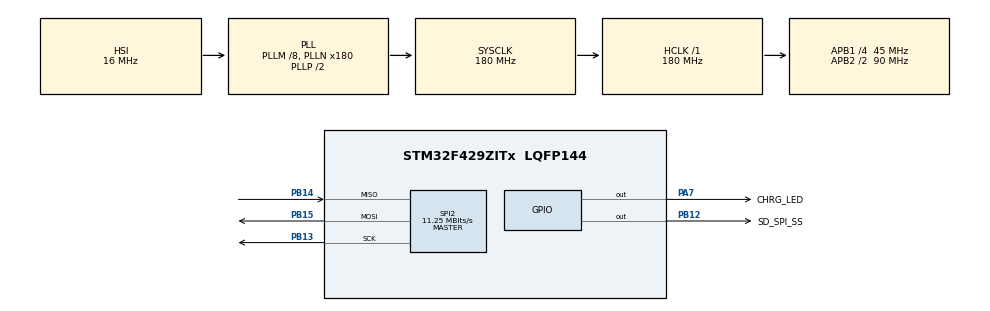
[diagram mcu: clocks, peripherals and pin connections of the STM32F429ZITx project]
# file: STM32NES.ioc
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FATFS._MAX_SS=512
FATFS._USE_LFN=1
FATFS._USE_STRFUNC=1
Mcu.Family=STM32F4
Mcu.Name=STM32F429ZITx
Mcu.Package=LQFP144
NVIC.PriorityGroup=NVIC_PRIORITYGROUP_4
PA7.GPIO_Label=CHRG_LED
PA7.PinState=GPIO_PIN_SET
PA7.Signal=GPIO_Output
PB12.GPIO_Label=SD_SPI_SS
PB12.PinState=GPIO_PIN_SET
PB12.Signal=GPIO_Output
PB13.Mode=Full_Duplex_Master
PB13.Signal=SPI2_SCK
PB14.Mode=Full_Duplex_Master
PB14.Signal=SPI2_MISO
PB15.Mode=Full_Duplex_Master
PB15.Signal=SPI2_MOSI
ProjectManager.HeapSize=0x200
ProjectManager.StackSize=0x400
ProjectManager.TargetToolchain=TrueSTUDIO
RCC.48MHZClocksFreq_Value=90000000
RCC.AHBFreq_Value=180000000
RCC.APB1CLKDivider=RCC_HCLK_DIV4
RCC.APB1Freq_Value=45000000
RCC.APB1TimFreq_Value=90000000
RCC.APB2CLKDivider=RCC_HCLK_DIV2
RCC.APB2Freq_Value=90000000
RCC.APB2TimFreq_Value=180000000
RCC.CortexFreq_Value=180000000
RCC.HCLKFreq_Value=180000000
RCC.HSE_VALUE=25000000
RCC.HSI_VALUE=16000000
RCC.LSE_VALUE=32768
RCC.PLLM=8
RCC.PLLN=180
RCC.SYSCLKFreq_VALUE=180000000
RCC.SYSCLKSource=RCC_SYSCLKSOURCE_PLLCLK
RCC.VCOOutputFreq_Value=360000000
SPI2.BaudRatePrescaler=SPI_BAUDRATEPRESCALER_4
SPI2.CalculateBaudRate=11.25 MBits/s
SPI2.Direction=SPI_DIRECTION_2LINES
SPI2.Mode=SPI_MODE_MASTER
SPI2.VirtualType=VM_MASTER
VP_FATFS_VS_Generic.Mode=User_defined
board=custom

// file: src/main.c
/* USER CODE BEGIN Header */
/**
 ******************************************************************************
 * @file           : main.c
 * @brief          : Main program body
 ******************************************************************************
 * This notice applies to any and all portions of this file
 * that are not between comment pairs USER CODE BEGIN and
 * USER CODE END. Other portions of this file, whether
 * inserted by the user or by software development tools
 * are owned by their respective copyright owners.
 *
 * Copyright (c) 2019 STMicroelectronics International N.V.
 * All rights reserved.
 *
 * Redistribution and use in source and binary forms, with or without
 * modification, are permitted, provided that the following conditions are met:
 *
 * 1. Redistribution of source code must retain the above copyright notice,
 *    this list of conditions and the following disclaimer.
 * 2. Redistributions in binary form must reproduce the above copyright notice,
 *    this list of conditions and the following disclaimer in the documentation
 *    and/or other materials provided with the distribution.
 * 3. Neither the name of STMicroelectronics nor the names of other
 *    contributors to this software may be used to endorse or promote products
 *    derived from this software without specific written permission.
 * 4. This software, including modifications and/or derivative works of this
 *    software, must execute solely and exclusively on microcontroller or
 *    microprocessor devices manufactured by or for STMicroelectronics.
 * 5. Redistribution and use of this software other than as permitted under
 *    this license is void and will automatically terminate your rights under
 *    this license.
 *
 * THIS SOFTWARE IS PROVIDED BY STMICROELECTRONICS AND CONTRIBUTORS "AS IS"
 * AND ANY EXPRESS, IMPLIED OR STATUTORY WARRANTIES, INCLUDING, BUT NOT
 * LIMITED TO, THE IMPLIED WARRANTIES OF MERCHANTABILITY, FITNESS FOR A
 * PARTICULAR PURPOSE AND NON-INFRINGEMENT OF THIRD PARTY INTELLECTUAL PROPERTY
 * RIGHTS ARE DISCLAIMED TO THE FULLEST EXTENT PERMITTED BY LAW. IN NO EVENT
 * SHALL STMICROELECTRONICS OR CONTRIBUTORS BE LIABLE FOR ANY DIRECT, INDIRECT,
 * INCIDENTAL, SPECIAL, EXEMPLARY, OR CONSEQUENTIAL DAMAGES (INCLUDING, BUT NOT
 * LIMITED TO, PROCUREMENT OF SUBSTITUTE GOODS OR SERVICES; LOSS OF USE, DATA,
 * OR PROFITS; OR BUSINESS INTERRUPTION) HOWEVER CAUSED AND ON ANY THEORY OF
 * LIABILITY, WHETHER IN CONTRACT, STRICT LIABILITY, OR TORT (INCLUDING
 * NEGLIGENCE OR OTHERWISE) ARISING IN ANY WAY OUT OF THE USE OF THIS SOFTWARE,
 * EVEN IF ADVISED OF THE POSSIBILITY OF SUCH DAMAGE.
 *
 ******************************************************************************
 */
/* USER CODE END Header */

#include "main.h"

#include "NES/cpu.h"
#include "NES/mapper.h"
#include "fatfs.h"

SPI_HandleTypeDef hspi2;
FATFS fs;

void SystemClock_Config(void);
static void MX_GPIO_Init(void);
static void MX_SPI2_Init(void);

int main(void) {

    /* MCU
     * Configuration--------------------------------------------------------*/

    /* Reset of all peripherals, Initializes the Flash interface and the
     * Systick. */
    HAL_Init();

    /* Configure the system clock */
    SystemClock_Config();

    /* Initialize all configured peripherals */
    MX_GPIO_Init();
    MX_FATFS_Init();
    MX_SPI2_Init();
    /* USER CODE BEGIN 2 */
    if (load_rom_from_sd(&fs, "smb.nes") != 0) return -1;
    cpu_init();
    /* USER CODE END 2 */

    /* Infinite loop */
    while (1) {
        cpu_run();
    }
}

void SystemClock_Config(void) {
    RCC_OscInitTypeDef RCC_OscInitStruct = { 0 };
    RCC_ClkInitTypeDef RCC_ClkInitStruct = { 0 };

    /**Configure the main internal regulator output voltage
     */
    __HAL_RCC_PWR_CLK_ENABLE();
    __HAL_PWR_VOLTAGESCALING_CONFIG(PWR_REGULATOR_VOLTAGE_SCALE1);
    /**Initializes the CPU, AHB and APB busses clocks
     */
    RCC_OscInitStruct.OscillatorType = RCC_OSCILLATORTYPE_HSI;
    RCC_OscInitStruct.HSIState = RCC_HSI_ON;
    RCC_OscInitStruct.HSICalibrationValue = RCC_HSICALIBRATION_DEFAULT;
    RCC_OscInitStruct.PLL.PLLState = RCC_PLL_ON;
    RCC_OscInitStruct.PLL.PLLSource = RCC_PLLSOURCE_HSI;
    RCC_OscInitStruct.PLL.PLLM = 8;
    RCC_OscInitStruct.PLL.PLLN = 180;
    RCC_OscInitStruct.PLL.PLLP = RCC_PLLP_DIV2;
    RCC_OscInitStruct.PLL.PLLQ = 4;
    if (HAL_RCC_OscConfig(&RCC_OscInitStruct) != HAL_OK) {
        Error_Handler();
    }
    /**Activate the Over-Drive mode
     */
    if (HAL_PWREx_EnableOverDrive() != HAL_OK) {
        Error_Handler();
    }
    /**Initializes the CPU, AHB and APB busses clocks
     */
    RCC_ClkInitStruct.ClockType = RCC_CLOCKTYPE_HCLK | RCC_CLOCKTYPE_SYSCLK |
                                  RCC_CLOCKTYPE_PCLK1 | RCC_CLOCKTYPE_PCLK2;
    RCC_ClkInitStruct.SYSCLKSource = RCC_SYSCLKSOURCE_PLLCLK;
    RCC_ClkInitStruct.AHBCLKDivider = RCC_SYSCLK_DIV1;
    RCC_ClkInitStruct.APB1CLKDivider = RCC_HCLK_DIV4;
    RCC_ClkInitStruct.APB2CLKDivider = RCC_HCLK_DIV2;

    if (HAL_RCC_ClockConfig(&RCC_ClkInitStruct, FLASH_LATENCY_5) != HAL_OK) {
        Error_Handler();
    }
}

static void MX_SPI2_Init(void) {

    /* SPI2 parameter configuration*/
    hspi2.Instance = SPI2;
    hspi2.Init.Mode = SPI_MODE_MASTER;
    hspi2.Init.Direction = SPI_DIRECTION_2LINES;
    hspi2.Init.DataSize = SPI_DATASIZE_8BIT;
    hspi2.Init.CLKPolarity = SPI_POLARITY_LOW;
    hspi2.Init.CLKPhase = SPI_PHASE_1EDGE;
    hspi2.Init.NSS = SPI_NSS_SOFT;
    hspi2.Init.BaudRatePrescaler = SPI_BAUDRATEPRESCALER_4;
    hspi2.Init.FirstBit = SPI_FIRSTBIT_MSB;
    hspi2.Init.TIMode = SPI_TIMODE_DISABLE;
    hspi2.Init.CRCCalculation = SPI_CRCCALCULATION_DISABLE;
    hspi2.Init.CRCPolynomial = 10;
    if (HAL_SPI_Init(&hspi2) != HAL_OK) {
        Error_Handler();
    }
}

static void MX_GPIO_Init(void) {
    GPIO_InitTypeDef GPIO_InitStruct = { 0 };

    /* GPIO Ports Clock Enable */
    __HAL_RCC_GPIOA_CLK_ENABLE();
    __HAL_RCC_GPIOB_CLK_ENABLE();

    /*Configure GPIO pin Output Level */
    HAL_GPIO_WritePin(CHRG_LED_GPIO_Port, CHRG_LED_Pin, GPIO_PIN_SET);

    /*Configure GPIO pin Output Level */
    HAL_GPIO_WritePin(SD_SPI_SS_GPIO_Port, SD_SPI_SS_Pin, GPIO_PIN_SET);

    /*Configure GPIO pin : CHRG_LED_Pin */
    GPIO_InitStruct.Pin = CHRG_LED_Pin;
    GPIO_InitStruct.Mode = GPIO_MODE_OUTPUT_PP;
    GPIO_InitStruct.Pull = GPIO_NOPULL;
    GPIO_InitStruct.Speed = GPIO_SPEED_FREQ_LOW;
    HAL_GPIO_Init(CHRG_LED_GPIO_Port, &GPIO_InitStruct);

    /*Configure GPIO pin : SD_SPI_SS_Pin */
    GPIO_InitStruct.Pin = SD_SPI_SS_Pin;
    GPIO_InitStruct.Mode = GPIO_MODE_OUTPUT_PP;
    GPIO_InitStruct.Pull = GPIO_NOPULL;
    GPIO_InitStruct.Speed = GPIO_SPEED_FREQ_LOW;
    HAL_GPIO_Init(SD_SPI_SS_GPIO_Port, &GPIO_InitStruct);
}

void Error_Handler(void) {
    /* USER CODE BEGIN Error_Handler_Debug */
    /* User can add his own implementation to report the HAL error return state
     */

    /* USER CODE END Error_Handler_Debug */
}

#ifdef USE_FULL_ASSERT
/**
 * @brief  Reports the name of the source file and the source line number
 *         where the assert_param error has occurred.
 * @param  file: pointer to the source file name
 * @param  line: assert_param error line source number
 * @retval None
 */
void assert_failed(uint8_t* file, uint32_t line) {
    /* USER CODE BEGIN 6 */
    /* User can add his own implementation to report the file name and line
       number, tex: printf("Wrong parameters value: file %s on line %d\r\n",
       file, line) */
    /* USER CODE END 6 */
}
#endif /* USE_FULL_ASSERT */

/************************ (C) COPYRIGHT STMicroelectronics *****END OF FILE****/
